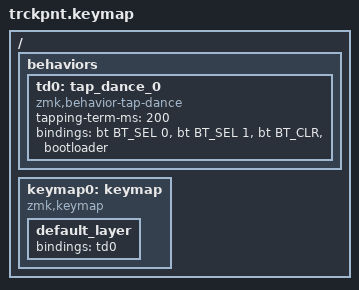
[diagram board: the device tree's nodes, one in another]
/*
 * Copyright (c) 2020 The ZMK Contributors
 *
 * SPDX-License-Identifier: MIT
 */

#include <behaviors.dtsi>
#include <dt-bindings/zmk/keys.h>
#include <dt-bindings/zmk/bt.h>

#include "trackpoint.dtsi"

/ {
    behaviors {
        td0: tap_dance_0 {
            compatible = "zmk,behavior-tap-dance";
            #binding-cells = <0>;
            tapping-term-ms = <200>;
            bindings = <&bt BT_SEL 0>, <&bt BT_SEL 1>, <&bt BT_CLR>, <&bootloader>;
        };
    };

    keymap0: keymap {
        compatible = "zmk,keymap";

        default_layer {
            bindings = <
                &td0
            >;
        };

    };
};
